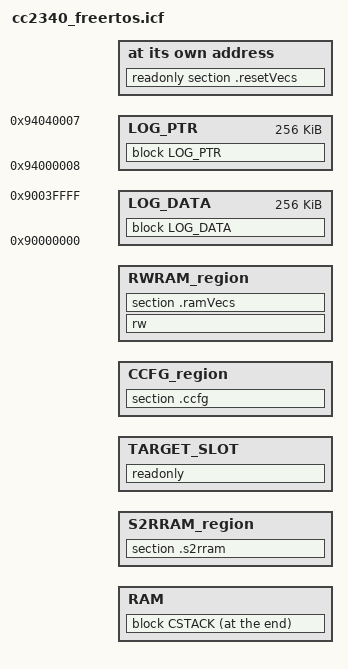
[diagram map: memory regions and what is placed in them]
/******************************************************************************

 @file  cc2340_freertos.icf

 @brief cc2340 family IAR ARM Linker Configuration File

        Imported Symbols
        Note: Linker defines are located in the IAR IDE project using
        --config_def in Options->Linker->Extra Options.

        Exported Symbols
        Note: Can be used as externs in C code.

 Group: WCS, BTS
 Target Device: cc23xx

 ******************************************************************************
 $License: BSD3 2018 - 2025 $
 ******************************************************************************
 
 
 *****************************************************************************/

include "ti_utils_build_linker.cmd.genmap";

////////////////////////////////////////////////////////////////////////////////
// Memory Sizes
////////////////////////////////////////////////////////////////////////////////
/* Define memory sizes for NVS, Flash, RAM, S2RRAM, and CCFG based on imported symbols */

/* Note: The assumption is that the NVS handle name is CONFIG_NVSINTERNAL in SysConfig */
if (isdefinedsymbol(ti_utils_build_GenMap_NVS_CONFIG_NVSINTERNAL_BASE) &&
    isdefinedsymbol(ti_utils_build_GenMap_NVS_CONFIG_NVSINTERNAL_SIZE))
{
  define symbol NVS_BASE = ti_utils_build_GenMap_NVS_CONFIG_NVSINTERNAL_BASE;
  define symbol NVS_SIZE = ti_utils_build_GenMap_NVS_CONFIG_NVSINTERNAL_SIZE;
}

if (isdefinedsymbol(ti_utils_build_GenMap_FLASH0_BASE) &&
    isdefinedsymbol(ti_utils_build_GenMap_FLASH0_SIZE))
{
  define symbol FLASH_BASE = ti_utils_build_GenMap_FLASH0_BASE;

  /* If NVS_BASE is defined, set it as the FLASH_SIZE                             */
  /* Note: The assumption is that the NVS slot is located in the end of the flash */
  if(isdefinedsymbol(NVS_BASE))
  {
    define symbol FLASH_SIZE = NVS_BASE;
  }
  else
  {
    define symbol FLASH_SIZE = ti_utils_build_GenMap_FLASH0_SIZE;
  }
}

if (isdefinedsymbol(ti_utils_build_GenMap_RAM0_BASE) &&
    isdefinedsymbol(ti_utils_build_GenMap_RAM0_SIZE))
{
  define symbol RAM_BASE  = ti_utils_build_GenMap_RAM0_BASE;
  define symbol RAM_SIZE  = ti_utils_build_GenMap_RAM0_SIZE;
}

if (isdefinedsymbol(ti_utils_build_GenMap_S2RRAM_BASE) &&
    isdefinedsymbol(ti_utils_build_GenMap_S2RRAM_SIZE))
{
  define symbol S2RRAM_BASE           = ti_utils_build_GenMap_S2RRAM_BASE;
  define symbol S2RRAM_SIZE           = ti_utils_build_GenMap_S2RRAM_SIZE;
}

if (isdefinedsymbol(ti_utils_build_GenMap_CCFG_BASE) &&
    isdefinedsymbol(ti_utils_build_GenMap_CCFG_SIZE))
{
  define symbol CCFG_BASE           = ti_utils_build_GenMap_CCFG_BASE;
  define symbol CCFG_SIZE           = ti_utils_build_GenMap_CCFG_SIZE;
}

if (isdefinedsymbol(ti_utils_build_GenMap_MS_OAD))
{
  define symbol MS_OAD = ti_utils_build_GenMap_MS_OAD;
}

if (isdefinedsymbol(ti_utils_build_GenMap_OAD_DUAL_IMAGE))
{
  define symbol OAD_DUAL_IMAGE = ti_utils_build_GenMap_OAD_DUAL_IMAGE;
}

if (isdefinedsymbol(ti_utils_build_GenMap_OAD_PERSISTENT))
{
  define symbol OAD_PERSISTENT = ti_utils_build_GenMap_OAD_PERSISTENT;
}

if (isdefinedsymbol(ti_utils_build_GenMap_APP_HDR_ADDR))
{
  define symbol APP_HDR_ADDR = ti_utils_build_GenMap_APP_HDR_ADDR;
}

if (isdefinedsymbol(ti_utils_build_GenMap_OAD_APP_ONCHIP))
{
  define symbol OAD_APP_ONCHIP = ti_utils_build_GenMap_OAD_APP_ONCHIP;
}

if (isdefinedsymbol(ti_utils_build_GenMap_OAD_APP_OFFCHIP))
{
  define symbol OAD_APP_OFFCHIP = ti_utils_build_GenMap_OAD_APP_OFFCHIP;
}

if (isdefinedsymbol(OAD_APP_OFFCHIP) || isdefinedsymbol(OAD_APP_ONCHIP) || isdefinedsymbol(OAD_PERSISTENT) || isdefinedsymbol(OAD_DUAL_IMAGE))
{
  define symbol MCU_HDR_SIZE  =  0x100;
  define symbol MCUBOOT_BASE  =  FLASH_BASE;
  define symbol MCUBOOT_SIZE  =  0x6000;
  define symbol APP_HDR_BASE  =  APP_HDR_ADDR;
  define symbol APP_BASE      = (APP_HDR_BASE + MCU_HDR_SIZE);
}

if (isdefinedsymbol(OAD_APP_ONCHIP) || isdefinedsymbol(OAD_PERSISTENT))
{
  define symbol PERSISTENT_HDR_BASE  = (MCUBOOT_BASE + MCUBOOT_SIZE);
  define symbol PERSISTENT_BASE      = (PERSISTENT_HDR_BASE + MCU_HDR_SIZE);
  define symbol PERSISTENT_SIZE      = (APP_HDR_BASE - PERSISTENT_BASE);
  define symbol APP_SIZE             = (FLASH_SIZE - APP_BASE);
}

if (isdefinedsymbol(OAD_APP_OFFCHIP))
{
  define symbol APP_SIZE      =  (FLASH_SIZE - APP_BASE);
}

if (isdefinedsymbol(OAD_DUAL_IMAGE))
{
  define symbol APP_SIZE      =  ((FLASH_SIZE - APP_HDR_ADDR)/2 - MCU_HDR_SIZE);
}

////////////////////////////////////////////////////////////////////////////////
// Memory Regions and Placements For RAM, S2RRAM, HSMTOP, CCFG, and Flash
////////////////////////////////////////////////////////////////////////////////

/* Define a memory region that covers the entire 4 GB addressable space */
define memory mem with size          = 4G;

////////////////////////////////////////////////////////////////////////////////
// MS-OAD - Include generated linker file for Multistep OAD
// Defines memory regions and section placements for split-image OAD.
// Must be after FLASH_BASE/FLASH_SIZE definitions and "define memory mem".
////////////////////////////////////////////////////////////////////////////////
if (isdefinedsymbol(MS_OAD))
{
    include "ti_ble_oad_linker.inc";
}

/* Define a region for the SRAM                                         */
if (isdefinedsymbol(RAM_BASE) && isdefinedsymbol(RAM_SIZE))
{
    define symbol RAM_START   = RAM_BASE;
    define symbol RAM_END     = RAM_BASE + RAM_SIZE - 1;
    define region RAM         = mem:[from RAM_START to RAM_END];
}

/* Define a region for the S2RRAM                                       */
if (isdefinedsymbol(S2RRAM_BASE) && isdefinedsymbol(S2RRAM_SIZE))
{
    /* Define a region for the on-chip S2RRAM
     * S2RRAM is intended for the S2R radio module, but it can also be used by the
     * application with some limitations. Please refer to the s2rram example.
     */
    define symbol S2RRAM_START    = S2RRAM_BASE;
    define symbol S2RRAM_END      = S2RRAM_BASE + S2RRAM_SIZE - 1;
    define region S2RRAM_region   = mem:[from S2RRAM_START to S2RRAM_END];
    /* Placing the section .s2rram in S2RRAM region. Only uninitialized
     * objects may be placed in this section.
     */
    place in S2RRAM_region           { section .s2rram };
    do not initialize                { section .s2rram };
}

/* Define a region for the flash                                        */
if (isdefinedsymbol(OAD_APP_OFFCHIP) || isdefinedsymbol(OAD_APP_ONCHIP) || isdefinedsymbol(OAD_PERSISTENT) || isdefinedsymbol(OAD_DUAL_IMAGE))
{
  define region MCUBOOT_SLOT         = mem:[from MCUBOOT_BASE to (MCUBOOT_BASE + MCUBOOT_SIZE - 1)];
  define region APP_HDR_SLOT         = mem:[from APP_HDR_BASE to (APP_BASE - 1)];
  define region APP_SLOT             = mem:[from APP_BASE to (APP_BASE + APP_SIZE - 1)];

  if (isdefinedsymbol(OAD_PERSISTENT))
  {
    define region PESISTENT_HDR_SLOT = mem:[from PERSISTENT_HDR_BASE to (PERSISTENT_HDR_BASE + MCU_HDR_SIZE - 1)];
    define region PERSITENT_SLOT     = mem:[from PERSISTENT_BASE to (PERSISTENT_BASE + PERSISTENT_SIZE - 1)];
    define symbol TARGET_BASE          = PERSISTENT_BASE;
    define region TARGET_SLOT          = PERSITENT_SLOT;
  }
  else
  {
    define symbol TARGET_BASE          = APP_BASE;
    define region TARGET_SLOT          = APP_SLOT;
  }
}
else if (!isdefinedsymbol(MS_OAD))
{
  define symbol FLASH_START          = FLASH_BASE;
  define symbol FLASH_END            = FLASH_SIZE - 1;
  define region FLASH                = mem:[from FLASH_START to FLASH_END];
  define symbol TARGET_BASE          = FLASH_START;
  define region TARGET_SLOT          = FLASH;
}

/* Define a region for the CCFG                                         */
if (!(isdefinedsymbol(OAD_APP_OFFCHIP) || isdefinedsymbol(OAD_APP_ONCHIP) || isdefinedsymbol(OAD_PERSISTENT) || isdefinedsymbol(OAD_DUAL_IMAGE)))
{
    if (isdefinedsymbol(CCFG_BASE) && isdefinedsymbol(CCFG_SIZE))
    {
      define symbol CCFG_START          = CCFG_BASE;
      define symbol CCFG_END            = CCFG_BASE + CCFG_SIZE - 1;
      define region CCFG_region         = mem:[from CCFG_START to CCFG_END];

      /* Define a placment for the CCFG                                     */
      place in CCFG_region              {section .ccfg};
      keep                              {section .ccfg};
    }
}

////////////////////////////////////////////////////////////////////////////////
// Memory Placement for other sections
////////////////////////////////////////////////////////////////////////////////
/* Define placement rules for various sections such as reset vectors, stack, and read-write data */
/* Define a placment for Interrupt Vector Table                          */
/* Note: When MS_OAD is defined, placement is handled by ti_ble_oad_linker.inc */
if (!isdefinedsymbol(MS_OAD))
{
    place at address mem:TARGET_BASE      { readonly section .resetVecs };
    place in TARGET_SLOT                  { readonly };
    keep                                  { readonly section .resetVecs };
}

/* Define a placment for CSTACK
 * Define CSTACK block to contain .stack section. This enables the IAR IDE
 * to properly show the stack content during debug. Place stack at end of
 * retention RAM, do not initialize (initializing the stack will destroy the
 * return address from the initialization code, causing the processor to branch
 * to zero and fault)
 */

/* Define the Stack size                                                   */
define symbol STACK_SIZE    = 1024;
define block CSTACK with alignment = 8, size = STACK_SIZE { section .stack };

/* Export stack top symbol. Used by startup file */
define exported symbol STACK_TOP     = RAM_END + 1;
define exported symbol STACK_START   = RAM_END - STACK_SIZE;

define region RWRAM_region  = mem:[from RAM_START to STACK_START];

/* Define a placment for RWDATA Vector Table                               */
place in RWRAM_region { rw, section .ramVecs };

/* Define a placment for CSTACK                                            */
place at end of RAM { block CSTACK };

////////////////////////////////////////////////////////////////////////////////
// Initialization
////////////////////////////////////////////////////////////////////////////////

initialize by copy { readwrite };

do not initialize
{
  section .ramVecs,
  section .noinit,
  section .stack,
};

////////////////////////////////////////////////////////////////////////////////
// Log data
////////////////////////////////////////////////////////////////////////////////
/* Explicitly placed off target for the storage of logging data.
 * The data placed here is NOT  loaded ont the target device.
 * This is part of 1 GB of external memory from 0x60000000 - 0x9FFFFFFF.
 * ARM memory map can be found here:
 * https://developer.arm.com/documentation/ddi0337/e/memory-map/about-the-memory-map
 */
define region LOG_DATA = mem:[from 0x90000000 to 0x9003FFFF];
define region LOG_PTR = mem:[from 0x94000008 to 0x94040007];
define block LOG_DATA  with size = 0x40000 { readonly section .log_data  };
define block LOG_PTR   with size = 0x40000 { readonly section .log_ptr* };
".log_data": place noload in LOG_DATA { block LOG_DATA };
".log_ptr": place noload in LOG_PTR { block LOG_PTR };
